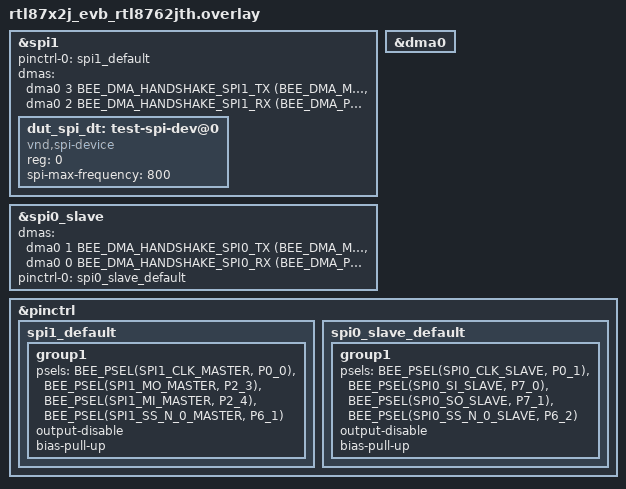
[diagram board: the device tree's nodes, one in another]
/*
 * Copyright (c) 2026, Realtek Semiconductor Corporation
 *
 * SPDX-License-Identifier: Apache-2.0
 */

&spi1 {
	status = "okay";
	pinctrl-0 = <&spi1_default>;
	pinctrl-names = "default";
	dmas = <&dma0 3 BEE_DMA_HANDSHAKE_SPI1_TX
		(BEE_DMA_M2P | BEE_DMA_SRC_INC | BEE_DMA_DST_FIXED | BEE_DMA_SRC_WIDTH_8BIT |
		 BEE_DMA_DST_WIDTH_8BIT | BEE_DMA_SRC_MSIZE(BEE_DMA_MSIZE_1) |
		 BEE_DMA_DST_MSIZE(BEE_DMA_MSIZE_1) | BEE_DMA_PRIORITY(3))>,
	       <&dma0 2 BEE_DMA_HANDSHAKE_SPI1_RX
		(BEE_DMA_P2M | BEE_DMA_SRC_FIXED | BEE_DMA_DST_INC | BEE_DMA_SRC_WIDTH_8BIT |
		 BEE_DMA_DST_WIDTH_8BIT | BEE_DMA_SRC_MSIZE(BEE_DMA_MSIZE_1) |
		 BEE_DMA_DST_MSIZE(BEE_DMA_MSIZE_4) | BEE_DMA_PRIORITY(0))>;
	dma-names = "tx", "rx";

	dut_spi_dt: test-spi-dev@0 {
		compatible = "vnd,spi-device";
		reg = <0>;
		spi-max-frequency = <800>;
	};
};

dut_spis: &spi0_slave {
	status = "okay";
	dmas = <&dma0 1 BEE_DMA_HANDSHAKE_SPI0_TX
		(BEE_DMA_M2P | BEE_DMA_SRC_INC | BEE_DMA_DST_FIXED | BEE_DMA_SRC_WIDTH_8BIT |
		 BEE_DMA_DST_WIDTH_8BIT | BEE_DMA_SRC_MSIZE(BEE_DMA_MSIZE_1) |
		 BEE_DMA_DST_MSIZE(BEE_DMA_MSIZE_1) | BEE_DMA_PRIORITY(1))>,
	       <&dma0 0 BEE_DMA_HANDSHAKE_SPI0_RX
		(BEE_DMA_P2M | BEE_DMA_SRC_FIXED | BEE_DMA_DST_INC | BEE_DMA_SRC_WIDTH_8BIT |
		 BEE_DMA_DST_WIDTH_8BIT | BEE_DMA_SRC_MSIZE(BEE_DMA_MSIZE_1) |
		 BEE_DMA_DST_MSIZE(BEE_DMA_MSIZE_1) | BEE_DMA_PRIORITY(0))>;
	dma-names = "tx", "rx";
	pinctrl-0 = <&spi0_slave_default>;
	pinctrl-names = "default";
};

&dma0 {
	status = "okay";
};

&pinctrl {
	spi1_default: spi1_default {
		group1 {
			psels = <BEE_PSEL(SPI1_CLK_MASTER, P0_0)>,
				<BEE_PSEL(SPI1_MO_MASTER, P2_3)>,
				<BEE_PSEL(SPI1_MI_MASTER, P2_4)>,
				<BEE_PSEL(SPI1_SS_N_0_MASTER, P6_1)>;
			output-disable;
			bias-pull-up;
		};
	};

	spi0_slave_default: spi0_slave_default {
		group1 {
			psels = <BEE_PSEL(SPI0_CLK_SLAVE, P0_1)>,
				<BEE_PSEL(SPI0_SI_SLAVE, P7_0)>,
				<BEE_PSEL(SPI0_SO_SLAVE, P7_1)>,
				<BEE_PSEL(SPI0_SS_N_0_SLAVE, P6_2)>;
			output-disable;
			bias-pull-up;
		};
	};
};
